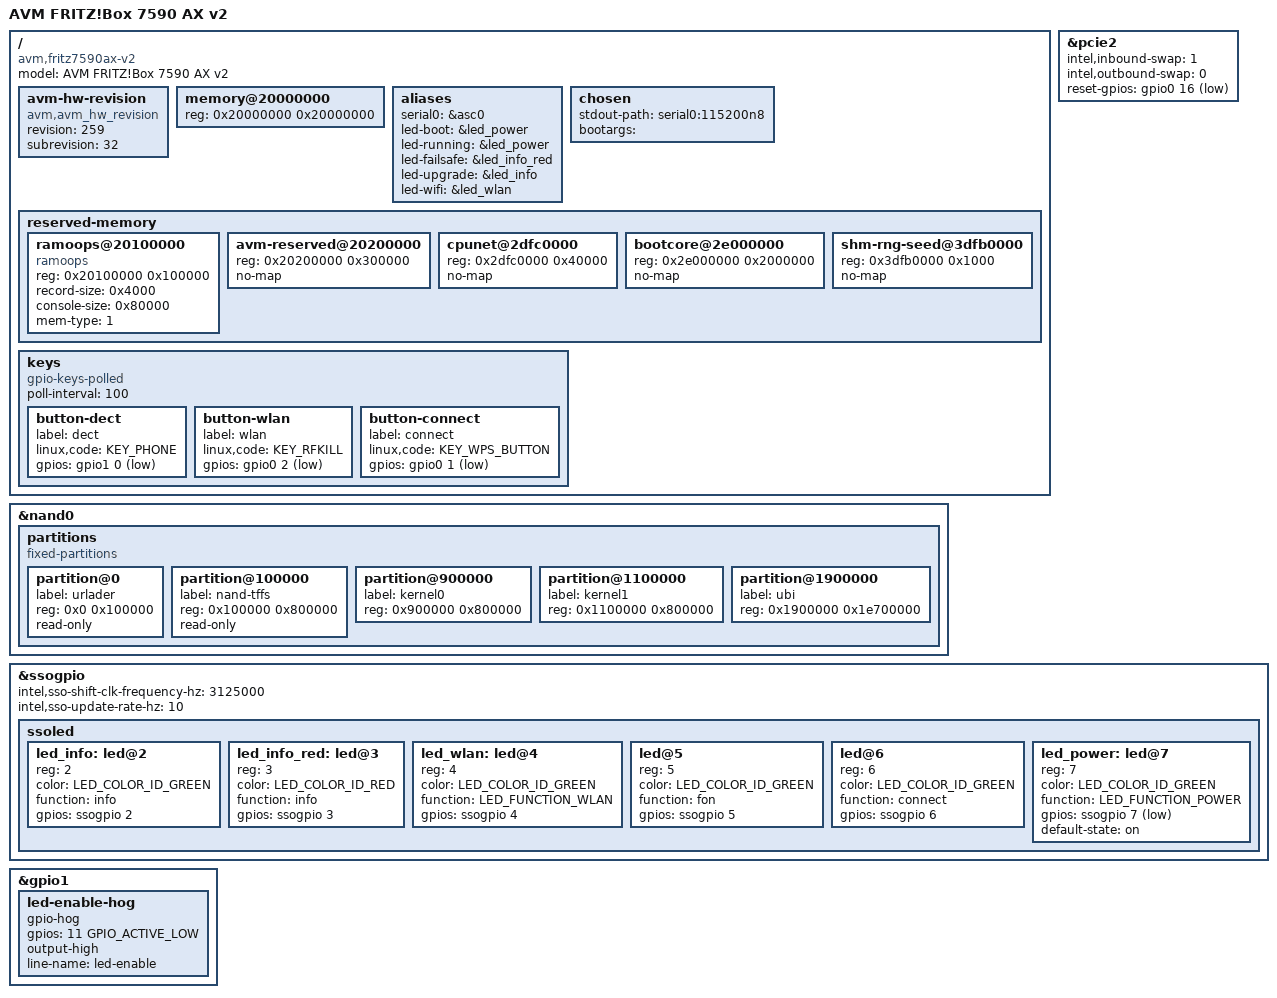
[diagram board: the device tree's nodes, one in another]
// SPDX-License-Identifier: GPL-2.0-only
// Copyright (C) 2026 Grische <github@grische.xyz>
/*
 * The AVM FRITZ!Box 7590 AX v2 is hardware revision HW259 on the GRX550 die
 * for HWSubRevision 31 and 32.
 * This file holds only its board-specific data. The SoC is described in
 * xrx500.dtsi, the board family in seale_avm.dtsi and the die variant in
 * seale_avm_grx550.dtsi.
 */
/dts-v1/;

#include <dt-bindings/gpio/gpio.h>
#include <dt-bindings/input/input.h>
#include <dt-bindings/leds/common.h>

#include "seale_avm_grx550.dtsi"

/ {
	model = "AVM FRITZ!Box 7590 AX v2";
	compatible = "avm,fritz7590ax-v2", "intel,xrx500";

	/*
	 * The boot image carries a table of device-tree blobs keyed by
	 * hardware sub-revision, and the boot loader looks the unit's value
	 * up in it. This tree takes 32, the value v2 units report, as the
	 * other boards' files take their unit's value. The vendor's own tree
	 * keys this revision at 0 and 31.
	 */
	avm-hw-revision {
		compatible = "avm,avm_hw_revision";
		revision = "259";
		subrevision = "32";
	};

	/*
	 * The node covers the full 512 MiB DDR part at PHYS_OFFSET.
	 *
	 * Only the first half of it has an uncached alias. Above
	 * PHYS_OFFSET + SZ_256M, the KSEG1 alias of a page is a register
	 * address rather than DRAM. That bound has not moved. What moved is
	 * where it is enforced. ZONE_DMA is sized to the window, and
	 * dma-direct takes every uncached coherent allocation from there.
	 * Holding the bound therefore no longer costs the board half its
	 * memory. Cached access is good across the whole node, since KSEG0
	 * covers all of it.
	 *
	 * The width is coupled to the boot container, and the coupling is
	 * exact rather than stylistic. The full width is safe only while the
	 * second CPU's boot loader stays unstarted. That firmware declares
	 * 256 MiB and programs a deny-all fabric region over everything
	 * above it. That region is precisely the half this node adds. The
	 * first access to that half then faults or hangs. There is no boot
	 * loader blob for this board. The way to keep that loader unstarted
	 * is therefore to ship the kernel in a single-kernel container,
	 * which is what the image recipe does.
	 */
	memory@20000000 {
		device_type = "memory";
		reg = <0x20000000 0x20000000>;
	};

	/*
	 * These aliases name the boot, failsafe and upgrade lamps for
	 * userspace. Without them, the boot-progress indication is silently
	 * absent.
	 */
	aliases {
		serial0 = &asc0;

		led-boot = &led_power;
		led-running = &led_power;
		led-failsafe = &led_info_red;
		led-upgrade = &led_info;
		led-wifi = &led_wlan;
	};

	chosen {
		stdout-path = "serial0:115200n8";
		/*
		 * This property is unused while MIPS_CMDLINE_BUILTIN_EXTEND
		 * is selected. It is present so that a board that needs its
		 * own arguments has somewhere to put them.
		 */
		bootargs = "";
	};

	/*
	 * Any region below that a device reaches through the uncached alias
	 * must stay under PHYS_OFFSET + SZ_256M. Above that address, the
	 * alias reaches registers, not DRAM. The seed buffer at the end is
	 * the one region that sits higher. It may, because it is no-map and
	 * this kernel never reaches it at all.
	 */
	reserved-memory {
		#address-cells = <1>;
		#size-cells = <1>;
		ranges;

		/*
		 * Crash persistence sits at the address the vendor's own
		 * device tree uses for it. The vendor's node is named
		 * ramoops@20500000, but its reg says 0x20100000. It takes
		 * 1 MiB of the 4 MiB region below _text. The zone sizes fill
		 * reg exactly, since fs/pstore/ram.c fails the whole probe if
		 * they overflow it.
		 */
		ramoops@20100000 {
			compatible = "ramoops";
			reg = <0x20100000 0x100000>;
			record-size = <0x4000>;
			console-size = <0x80000>;
			mem-type = <1>;
		};

		/*
		 * This is the rest of the region that seale_avm.dtsi reserves.
		 * The crash log above has taken its first megabyte.
		 */
		/delete-node/ avm-reserved@20100000;

		avm-reserved@20200000 {
			reg = <0x20200000 0x300000>;
			no-map;
		};

		/*
		 * This region is owned by the second CPU's boot loader. The
		 * vendor ships a device tree of its own for that core. The
		 * region is no-map so that this kernel never maps another
		 * CPU's memory.
		 */
		cpunet@2dfc0000 {
			reg = <0x2dfc0000 0x40000>;
			no-map;
		};

		bootcore@2e000000 {
			reg = <0x2e000000 0x2000000>;
			no-map;
		};

		/*
		 * This is a fixed-address seed buffer shared with the second
		 * CPU. It is reserved no-map so that nothing here maps or
		 * reads it.
		 */
		shm-rng-seed@3dfb0000 {
			reg = <0x3dfb0000 0x1000>;
			no-map;
		};
	};
};

/*
 * The flash is a Toshiba BENAND part of 512 MiB with a 4 KiB page. Its
 * geometry is self-identified. The partition map is the one the vendor boot
 * loader installs, so a vendor recovery can hand the kernel back to the
 * original firmware without remapping flash. It is not the FRITZ!Box 7590's
 * map, so that board's images must never be written to this flash.
 */
&nand0 {
	partitions {
		compatible = "fixed-partitions";
		#address-cells = <1>;
		#size-cells = <1>;

		/*
		 * This partition holds the first-stage boot loader. It is
		 * read-only, because overwriting it bricks the device past the
		 * point of recovery without an external programmer.
		 */
		partition@0 {
			label = "urlader";
			reg = <0x0 0x100000>;
			read-only;
		};

		/*
		 * This is the AVM TFFS environment. It holds the only copy of
		 * this unit's identity, its MAC addresses and serial number.
		 * It is never written from Linux. Erasing it cannot be undone.
		 */
		partition@100000 {
			label = "nand-tffs";
			reg = <0x100000 0x800000>;
			read-only;
		};

		/*
		 * Two 8 MiB kernel slots follow, named by position. Which one
		 * is active is boot-loader run-time state. The linux_fs_start
		 * variable selects between them. No label may therefore claim
		 * to be the active one.
		 */
		partition@900000 {
			label = "kernel0";
			reg = <0x900000 0x800000>;
		};

		partition@1100000 {
			label = "kernel1";
			reg = <0x1100000 0x800000>;
		};

		/* UBI holds rootfs and rootfs_data up to the 512 MiB mark. */
		partition@1900000 {
			label = "ubi";
			reg = <0x1900000 0x1e700000>;
		};
	};
};

/*
 * RC0 and RC1 carry two Intel/MaxLinear WAV600 Wi-Fi parts, PCI ID 8086:09d0.
 * The WAV624 on RC0 serves 5 GHz and the WAV614 on RC1 serves 2.4 GHz. No
 * in-tree driver supports them. RC2 carries a DSL part of the VRX618 family,
 * PCI ID 8086:09aa, which has no in-tree driver either. Inbound byte
 * swapping stays on for this part.
 */
&pcie2 {
	status = "okay";
	intel,inbound-swap = <1>;
	intel,outbound-swap = <0>;
	reset-gpios = <&gpio0 16 GPIO_ACTIVE_LOW>;
};

/*
 * Front-panel lamps.
 *
 * The shift-register controller they hang off is a GRX550 fact and lives in
 * seale_avm_grx550.dtsi. What is board data is which of its eight pins are
 * populated and what each one drives. All six declared here are visible
 * lamps.
 *
 * The shift clock runs at 3.125 MHz, the rate the vendor's tree asks for on
 * this board's FPGA-less sub-revision.
 *
 * The die layer's 250 kHz update rate selects a timer outside the SSO block,
 * which nothing in this kernel programs. Unless that timer already runs, no
 * output word ever reaches the shift register. A 10 Hz rate is the fastest
 * that selects the SSO block's own divided clock instead.
 */
&ssogpio {
	intel,sso-shift-clk-frequency-hz = <3125000>;
	intel,sso-update-rate-hz = <10>;

	/*
	 * The child must be named "ssoled", because the driver matches on
	 * the node name. The LEDs carry no label property, since colour and
	 * function compose the ABI-visible LED name.
	 */
	ssoled {
		#address-cells = <1>;
		#size-cells = <0>;

		/*
		 * Pin 0 is left undeclared, since this sub-revision has no
		 * FPGA to read a brightness carrier from it.
		 */

		/* The two halves of the bicolour info lamp. */
		led_info: led@2 {
			reg = <2>;
			color = <LED_COLOR_ID_GREEN>;
			function = "info";
			gpios = <&ssogpio 2 GPIO_ACTIVE_HIGH>;
		};

		led_info_red: led@3 {
			reg = <3>;
			color = <LED_COLOR_ID_RED>;
			function = "info";
			gpios = <&ssogpio 3 GPIO_ACTIVE_HIGH>;
		};

		led_wlan: led@4 {
			reg = <4>;
			color = <LED_COLOR_ID_GREEN>;
			function = LED_FUNCTION_WLAN;
			gpios = <&ssogpio 4 GPIO_ACTIVE_HIGH>;
		};

		led@5 {
			reg = <5>;
			color = <LED_COLOR_ID_GREEN>;
			function = "fon";
			gpios = <&ssogpio 5 GPIO_ACTIVE_HIGH>;
		};

		led@6 {
			reg = <6>;
			color = <LED_COLOR_ID_GREEN>;
			function = "connect";
			gpios = <&ssogpio 6 GPIO_ACTIVE_HIGH>;
		};

		/*
		 * The lamp is lit as soon as the driver probes. It is already
		 * on when the kernel starts, and blinking it off mid-boot would
		 * read as a failed boot. The line is active low.
		 */
		led_power: led@7 {
			reg = <7>;
			color = <LED_COLOR_ID_GREEN>;
			function = LED_FUNCTION_POWER;
			gpios = <&ssogpio 7 GPIO_ACTIVE_LOW>;
			default-state = "on";
		};
	};
};

/* The keys are polled, because the GPIO banks publish no irq domain. */
/ {
	keys {
		compatible = "gpio-keys-polled";
		poll-interval = <100>;

		button-dect {
			label = "dect";
			linux,code = <KEY_PHONE>;
			gpios = <&gpio1 0 GPIO_ACTIVE_LOW>;
		};

		button-wlan {
			label = "wlan";
			linux,code = <KEY_RFKILL>;
			gpios = <&gpio0 2 GPIO_ACTIVE_LOW>;
		};

		button-connect {
			label = "connect";
			linux,code = <KEY_WPS_BUTTON>;
			gpios = <&gpio0 1 GPIO_ACTIVE_LOW>;
		};
	};
};

/*
 * The master LED enable is a plain GPIO rather than an SSO pin. Nothing in
 * this tree consumes it, which is why it is hogged. The whole panel is dark
 * while it is low.
 */
&gpio1 {
	led-enable-hog {
		gpio-hog;
		gpios = <11 GPIO_ACTIVE_LOW>;
		output-high;
		line-name = "led-enable";
	};
};
